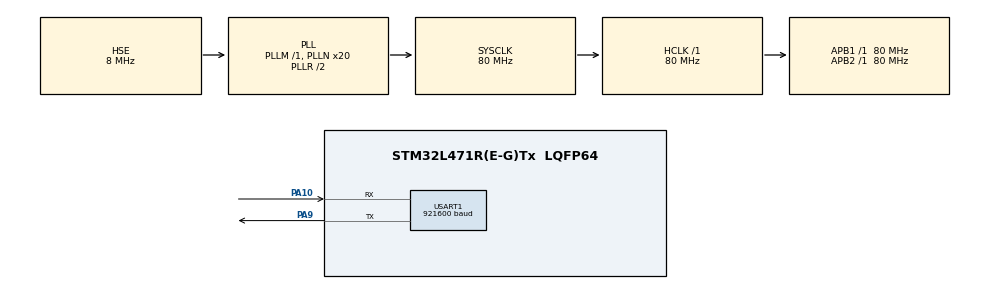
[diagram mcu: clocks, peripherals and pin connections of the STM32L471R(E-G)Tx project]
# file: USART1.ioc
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Mcu.Family=STM32L4
Mcu.Name=STM32L471R(E-G)Tx
Mcu.Package=LQFP64
NVIC.PriorityGroup=NVIC_PRIORITYGROUP_4
NVIC.USART1_IRQn=true\:0\:0\:false\:false\:true\:true
PA10.Mode=Asynchronous
PA10.Signal=USART1_RX
PA13\ (JTMS-SWDIO).Mode=Serial_Wire
PA13\ (JTMS-SWDIO).Signal=SYS_JTMS-SWDIO
PA14\ (JTCK-SWCLK).Mode=Serial_Wire
PA14\ (JTCK-SWCLK).Signal=SYS_JTCK-SWCLK
PA9.Mode=Asynchronous
PA9.Signal=USART1_TX
PH0-OSC_IN\ (PH0).Mode=HSE-External-Oscillator
PH0-OSC_IN\ (PH0).Signal=RCC_OSC_IN
PH1-OSC_OUT\ (PH1).Mode=HSE-External-Oscillator
PH1-OSC_OUT\ (PH1).Signal=RCC_OSC_OUT
ProjectManager.HeapSize=0x200
ProjectManager.StackSize=0x400
ProjectManager.TargetToolchain=MDK-ARM V5
RCC.ADCFreq_Value=32000000
RCC.AHBFreq_Value=80000000
RCC.APB1Freq_Value=80000000
RCC.APB1TimFreq_Value=80000000
RCC.APB2Freq_Value=80000000
RCC.APB2TimFreq_Value=80000000
RCC.CortexFreq_Value=80000000
RCC.HCLKFreq_Value=80000000
RCC.HSE_VALUE=8000000
RCC.HSI_VALUE=16000000
RCC.LSE_VALUE=32768
RCC.MSI_VALUE=4000000
RCC.PLLN=20
RCC.PLLSourceVirtual=RCC_PLLSOURCE_HSE
RCC.SYSCLKFreq_VALUE=80000000
RCC.SYSCLKSource=RCC_SYSCLKSOURCE_PLLCLK
RCC.VCOOutputFreq_Value=160000000
USART1.BaudRate=921600
USART1.VirtualMode-Asynchronous=VM_ASYNC
board=custom

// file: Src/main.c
/* USER CODE BEGIN Header */
/**
  ******************************************************************************
  * @file           : main.c
  * @brief          : Main program body
  ******************************************************************************
  ** This notice applies to any and all portions of this file
  * that are not between comment pairs USER CODE BEGIN and
  * USER CODE END. Other portions of this file, whether
  * inserted by the user or by software development tools
  * are owned by their respective copyright owners.
  *
  * COPYRIGHT(c) 2019 STMicroelectronics
  *
  * Redistribution and use in source and binary forms, with or without modification,
  * are permitted provided that the following conditions are met:
  *   1. Redistributions of source code must retain the above copyright notice,
  *      this list of conditions and the following disclaimer.
  *   2. Redistributions in binary form must reproduce the above copyright notice,
  *      this list of conditions and the following disclaimer in the documentation
  *      and/or other materials provided with the distribution.
  *   3. Neither the name of STMicroelectronics nor the names of its contributors
  *      may be used to endorse or promote products derived from this software
  *      without specific prior written permission.
  *
  * THIS SOFTWARE IS PROVIDED BY THE COPYRIGHT HOLDERS AND CONTRIBUTORS "AS IS"
  * AND ANY EXPRESS OR IMPLIED WARRANTIES, INCLUDING, BUT NOT LIMITED TO, THE
  * IMPLIED WARRANTIES OF MERCHANTABILITY AND FITNESS FOR A PARTICULAR PURPOSE ARE
  * DISCLAIMED. IN NO EVENT SHALL THE COPYRIGHT HOLDER OR CONTRIBUTORS BE LIABLE
  * FOR ANY DIRECT, INDIRECT, INCIDENTAL, SPECIAL, EXEMPLARY, OR CONSEQUENTIAL
  * DAMAGES (INCLUDING, BUT NOT LIMITED TO, PROCUREMENT OF SUBSTITUTE GOODS OR
  * SERVICES; LOSS OF USE, DATA, OR PROFITS; OR BUSINESS INTERRUPTION) HOWEVER
  * CAUSED AND ON ANY THEORY OF LIABILITY, WHETHER IN CONTRACT, STRICT LIABILITY,
  * OR TORT (INCLUDING NEGLIGENCE OR OTHERWISE) ARISING IN ANY WAY OUT OF THE USE
  * OF THIS SOFTWARE, EVEN IF ADVISED OF THE POSSIBILITY OF SUCH DAMAGE.
  *
  ******************************************************************************
  */
/* USER CODE END Header */

#include "main.h"
#include "usart.h"
#include "gpio.h"

void SystemClock_Config(void);
/* USER CODE BEGIN PFP */

#include "serial.h"
void *console_port = NULL;

static void console_getchar( uint8_t c)
{
    //putchar( c ); //这是一个一个接收的函数 没有逻辑 收到就随即发出去了
    printf("%c",c);
}

void serial_console_init( void )
{
    console_port = serial.open("serial1");//匹配1号串口
    if( console_port == NULL)  return ;
    serial.init(console_port  , 921600 , console_getchar);//此函数以后才可以printf因为下面的函数在实在了
}
int fputc(int ch, FILE *f)
{
	serial.putc(console_port, ch);
	return ch;
}

/* USER CODE END PFP */

int main(void)
{

  /* MCU Configuration--------------------------------------------------------*/

  /* Reset of all peripherals, Initializes the Flash interface and the Systick. */
  HAL_Init();

  /* Configure the system clock */
  SystemClock_Config();

  /* Initialize all configured peripherals */
  MX_GPIO_Init();
  MX_USART1_UART_Init();
  /* USER CODE BEGIN 2 */

	serial_console_init();

  /* USER CODE END 2 */

  /* Infinite loop */
  while (1)
  {
		//printf("\r\n%s\r\n",__FUNCTION__);
		HAL_Delay(800);
  }
}

void SystemClock_Config(void)
{
  RCC_OscInitTypeDef RCC_OscInitStruct = {0};
  RCC_ClkInitTypeDef RCC_ClkInitStruct = {0};
  RCC_PeriphCLKInitTypeDef PeriphClkInit = {0};

  /**Initializes the CPU, AHB and APB busses clocks
  */
  RCC_OscInitStruct.OscillatorType = RCC_OSCILLATORTYPE_HSE;
  RCC_OscInitStruct.HSEState = RCC_HSE_ON;
  RCC_OscInitStruct.PLL.PLLState = RCC_PLL_ON;
  RCC_OscInitStruct.PLL.PLLSource = RCC_PLLSOURCE_HSE;
  RCC_OscInitStruct.PLL.PLLM = 1;
  RCC_OscInitStruct.PLL.PLLN = 20;
  RCC_OscInitStruct.PLL.PLLP = RCC_PLLP_DIV7;
  RCC_OscInitStruct.PLL.PLLQ = RCC_PLLQ_DIV2;
  RCC_OscInitStruct.PLL.PLLR = RCC_PLLR_DIV2;
  if (HAL_RCC_OscConfig(&RCC_OscInitStruct) != HAL_OK)
  {
    Error_Handler();
  }
  /**Initializes the CPU, AHB and APB busses clocks
  */
  RCC_ClkInitStruct.ClockType = RCC_CLOCKTYPE_HCLK|RCC_CLOCKTYPE_SYSCLK
                              |RCC_CLOCKTYPE_PCLK1|RCC_CLOCKTYPE_PCLK2;
  RCC_ClkInitStruct.SYSCLKSource = RCC_SYSCLKSOURCE_PLLCLK;
  RCC_ClkInitStruct.AHBCLKDivider = RCC_SYSCLK_DIV1;
  RCC_ClkInitStruct.APB1CLKDivider = RCC_HCLK_DIV1;
  RCC_ClkInitStruct.APB2CLKDivider = RCC_HCLK_DIV1;

  if (HAL_RCC_ClockConfig(&RCC_ClkInitStruct, FLASH_LATENCY_4) != HAL_OK)
  {
    Error_Handler();
  }
  PeriphClkInit.PeriphClockSelection = RCC_PERIPHCLK_USART1;
  PeriphClkInit.Usart1ClockSelection = RCC_USART1CLKSOURCE_PCLK2;
  if (HAL_RCCEx_PeriphCLKConfig(&PeriphClkInit) != HAL_OK)
  {
    Error_Handler();
  }
  /**Configure the main internal regulator output voltage
  */
  if (HAL_PWREx_ControlVoltageScaling(PWR_REGULATOR_VOLTAGE_SCALE1) != HAL_OK)
  {
    Error_Handler();
  }
}

void Error_Handler(void)
{
}

/************************ (C) COPYRIGHT STMicroelectronics *****END OF FILE****/
